# 3066H register map
File version: 1.0
Registers are 32-bit, access per field, reset 0x0 unless marked. A register's access mark holds for its fields unless they carry their own. Offsets are from the block's base; [hi:lo] are bit positions; {n}, {i} and the like mark numbered series; 'fields as' and 'values as' point back to an identical list.

## IOCMG_CORE — IOCMG_CORE peripheral interface
Base 0x147F0000
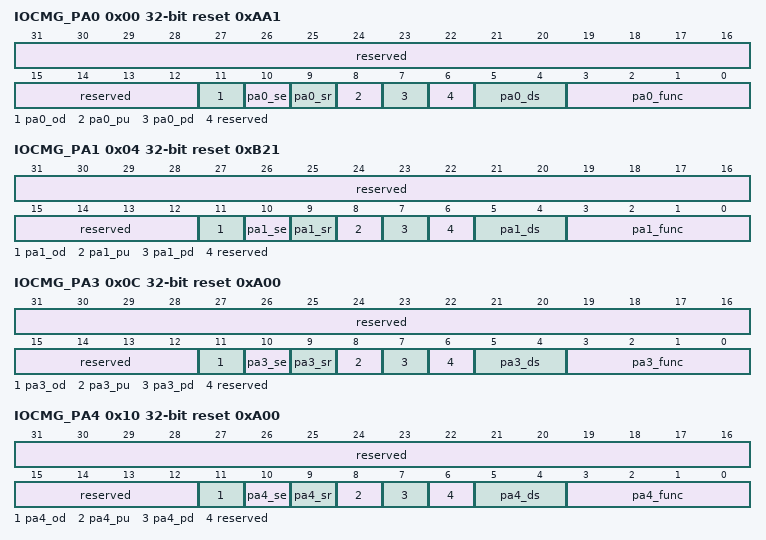
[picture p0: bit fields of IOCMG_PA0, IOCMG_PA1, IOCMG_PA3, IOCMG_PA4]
0x00 IOCMG_PA0 reset 0xAA1 — IOCMG_PA0为PA0管脚控制寄存器。
  [31:12] reserved ro — 保留。
  [11] pa0_od rw — 管脚开漏输出控制。 0：打开； 1：关闭。
  [10] pa0_se rw — 管脚施密特输入控制。 0：关闭； 1：打开。
  [9] pa0_sr rw — 管脚电平转换速率控制。 0：快沿输出； 1：慢沿输出。
  [8] pa0_pu rw — 管脚上拉控制。 0：关闭； 1：打开。
  [7] pa0_pd rw — 管脚下拉控制。 0：关闭； 1：打开。
  [6] reserved ro — 保留。
  [5:4] pa0_ds rw — 管脚驱动能力选择（档位越高，驱动能力越大）。 00：档位1； 01：档位2； 10：档位3； 11：档位4。
  [3:0] pa0_func rw — 管脚复用功能选择。 具体复用功能请参见《3066H系列数据手册》。
0x04 IOCMG_PA1 reset 0xB21 — IOCMG_PA1为PA1管脚控制寄存器。
  [31:12] reserved ro — 保留。
  [11] pa1_od rw — 管脚开漏输出控制。 0：打开； 1：关闭。
  [10] pa1_se rw — 管脚施密特输入控制。 0：关闭； 1：打开。
  [9] pa1_sr rw — 管脚电平转换速率控制。 0：快沿输出； 1：慢沿输出。
  [8] pa1_pu rw — 管脚上拉控制。 0：关闭； 1：打开。
  [7] pa1_pd rw — 管脚下拉控制。 0：关闭； 1：打开。
  [6] reserved ro — 保留。
  [5:4] pa1_ds rw — 管脚驱动能力选择（档位越高，驱动能力越大）。 00：档位1； 01：档位2； 10：档位3； 11：档位4。
  [3:0] pa1_func rw — 管脚复用功能选择。 具体复用功能请参见《3066H系列数据手册》。
0x0C IOCMG_PA3 reset 0xA00 — IOCMG_PA3为PA3管脚控制寄存器。
  [31:12] reserved ro — 保留。
  [11] pa3_od rw — 管脚开漏输出控制。 0：打开； 1：关闭。
  [10] pa3_se rw — 管脚施密特输入控制。 0：关闭； 1：打开。
  [9] pa3_sr rw — 管脚电平转换速率控制。 0：快沿输出； 1：慢沿输出。
  [8] pa3_pu rw — 管脚上拉控制。 0：关闭； 1：打开。
  [7] pa3_pd rw — 管脚下拉控制。 0：关闭； 1：打开。
  [6] reserved ro — 保留。
  [5:4] pa3_ds rw — 管脚驱动能力选择（档位越高，驱动能力越大）。 00：档位1； 01：档位2； 10：档位3； 11：档位4。
  [3:0] pa3_func rw — 管脚复用功能选择。 具体复用功能请参见《3066H系列数据手册》。
0x10 IOCMG_PA4 reset 0xA00 — IOCMG_PA4为PA4管脚控制寄存器。
  [31:12] reserved ro — 保留。
  [11] pa4_od rw — 管脚开漏输出控制。 0：打开； 1：关闭。
  [10] pa4_se rw — 管脚施密特输入控制。 0：关闭； 1：打开。
  [9] pa4_sr rw — 管脚电平转换速率控制。 0：快沿输出； 1：慢沿输出。
  [8] pa4_pu rw — 管脚上拉控制。 0：关闭； 1：打开。
  [7] pa4_pd rw — 管脚下拉控制。 0：关闭； 1：打开。
  [6] reserved ro — 保留。
  [5:4] pa4_ds rw — 管脚驱动能力选择（档位越高，驱动能力越大）。 00：档位1； 01：档位2； 10：档位3； 11：档位4。
  [3:0] pa4_func rw — 管脚复用功能选择。 具体复用功能请参见《3066H系列数据手册》。
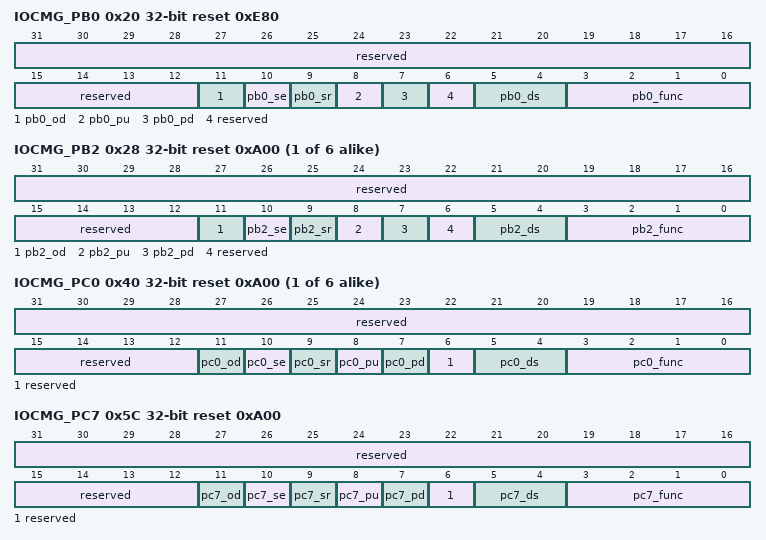
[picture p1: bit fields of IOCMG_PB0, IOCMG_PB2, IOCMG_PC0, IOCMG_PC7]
0x20 IOCMG_PB0 reset 0xE80 — IOCMG_PB0为PB0管脚控制寄存器。
  [31:12] reserved ro — 保留。
  [11] pb0_od rw — 管脚开漏输出控制。 0：打开； 1：关闭。
  [10] pb0_se rw — 管脚施密特输入控制。 0：关闭； 1：打开。
  [9] pb0_sr rw — 管脚电平转换速率控制。 0：快沿输出； 1：慢沿输出。
  [8] pb0_pu rw — 管脚上拉控制。 0：关闭； 1：打开。
  [7] pb0_pd rw — 管脚下拉控制。 0：关闭； 1：打开。
  [6] reserved ro — 保留。
  [5:4] pb0_ds rw — 管脚驱动能力选择（档位越高，驱动能力越大）。 00：档位1； 01：档位2； 10：档位3； 11：档位4。
  [3:0] pb0_func rw — 管脚复用功能选择。 具体复用功能请参见《3066H系列数据手册》。
{0x20+4i} IOCMG_PB{i} reset 0xA00 (i=2..7) — IOCMG_PB{i}为PB{i}管脚控制寄存器。
  [31:12] reserved ro — 保留。
  [11] pb{i}_od rw — 管脚开漏输出控制。 0：打开； 1：关闭。
  [10] pb{i}_se rw — 管脚施密特输入控制。 0：关闭； 1：打开。
  [9] pb{i}_sr rw — 管脚电平转换速率控制。 0：快沿输出； 1：慢沿输出。
  [8] pb{i}_pu rw — 管脚上拉控制。 0：关闭； 1：打开。
  [7] pb{i}_pd rw — 管脚下拉控制。 0：关闭； 1：打开。
  [6] reserved ro — 保留。
  [5:4] pb{i}_ds rw — 管脚驱动能力选择（档位越高，驱动能力越大）。 00：档位1； 01：档位2； 10：档位3； 11：档位4。
  [3:0] pb{i}_func rw — 管脚复用功能选择。 具体复用功能请参见《3066H系列数据手册》。
{0x40+4i} IOCMG_PC{i} reset 0xA00 (i=0..5) — IOCMG_PC{i}为PC{i}管脚控制寄存器。
  [31:12] reserved ro — 保留。
  [11] pc{i}_od rw — 管脚开漏输出控制。 0：打开； 1：关闭。
  [10] pc{i}_se rw — 管脚施密特输入控制。 0：关闭； 1：打开。
  [9] pc{i}_sr rw — 管脚电平转换速率控制。 0：快沿输出； 1：慢沿输出。
  [8] pc{i}_pu rw — 管脚上拉控制。 0：关闭； 1：打开。
  [7] pc{i}_pd rw — 管脚下拉控制。 0：关闭； 1：打开。
  [6] reserved ro — 保留。
  [5:4] pc{i}_ds rw — 管脚驱动能力选择（档位越高，驱动能力越大）。 00：档位1； 01：档位2； 10：档位3； 11：档位4。
  [3:0] pc{i}_func rw — 管脚复用功能选择。 具体复用功能请参见《3066H系列数据手册》。
0x5C IOCMG_PC7 reset 0xA00 — IOCMG_PC7为PC7管脚控制寄存器。
  [31:12] reserved ro — 保留。
  [11] pc7_od rw — 管脚开漏输出控制。 0：打开； 1：关闭。
  [10] pc7_se rw — 管脚施密特输入控制。 0：关闭； 1：打开。
  [9] pc7_sr rw — 管脚电平转换速率控制。 0：快沿输出； 1：慢沿输出。
  [8] pc7_pu rw — 管脚上拉控制。 0：关闭； 1：打开。
  [7] pc7_pd rw — 管脚下拉控制。 0：关闭； 1：打开。
  [6] reserved ro — 保留。
  [5:4] pc7_ds rw — 管脚驱动能力选择（档位越高，驱动能力越大）。 00：档位1； 01：档位2； 10：档位3； 11：档位4。
  [3:0] pc7_func rw — 管脚复用功能选择。 具体复用功能请参见《3066H系列数据手册》。
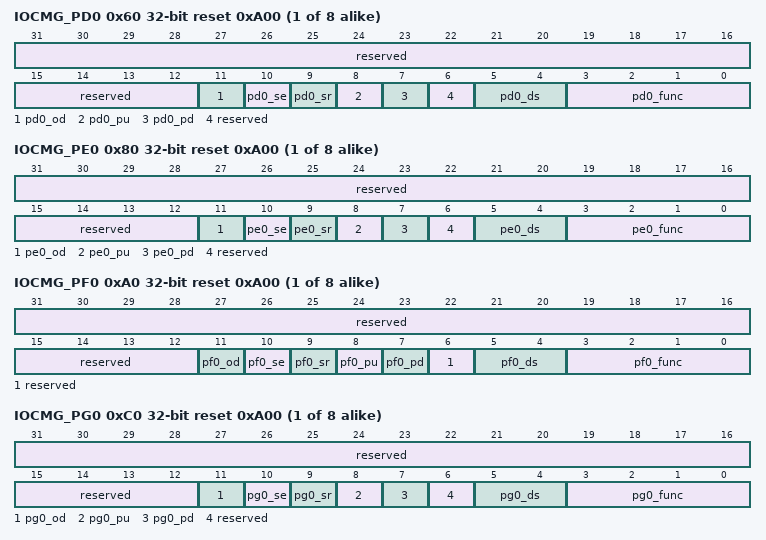
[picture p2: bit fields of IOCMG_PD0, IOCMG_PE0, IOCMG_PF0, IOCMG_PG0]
{0x60+4i} IOCMG_PD{i} reset 0xA00 (i=0..7) — IOCMG_PD{i}为PD{i}管脚控制寄存器。
  [31:12] reserved ro — 保留。
  [11] pd{i}_od rw — 管脚开漏输出控制。 0：打开； 1：关闭。
  [10] pd{i}_se rw — 管脚施密特输入控制。 0：关闭； 1：打开。
  [9] pd{i}_sr rw — 管脚电平转换速率控制。 0：快沿输出； 1：慢沿输出。
  [8] pd{i}_pu rw — 管脚上拉控制。 0：关闭； 1：打开。
  [7] pd{i}_pd rw — 管脚下拉控制。 0：关闭； 1：打开。
  [6] reserved ro — 保留。
  [5:4] pd{i}_ds rw — 管脚驱动能力选择（档位越高，驱动能力越大）。 00：档位1； 01：档位2； 10：档位3； 11：档位4。
  [3:0] pd{i}_func rw — 管脚复用功能选择。 具体复用功能请参见《3066H系列数据手册》。
{0x80+4i} IOCMG_PE{i} reset 0xA00 (i=0..7) — IOCMG_PE{i}为PE{i}管脚控制寄存器。
  [31:12] reserved ro — 保留。
  [11] pe{i}_od rw — 管脚开漏输出控制。 0：打开； 1：关闭。
  [10] pe{i}_se rw — 管脚施密特输入控制。 0：关闭； 1：打开。
  [9] pe{i}_sr rw — 管脚电平转换速率控制。 0：快沿输出； 1：慢沿输出。
  [8] pe{i}_pu rw — 管脚上拉控制。 0：关闭； 1：打开。
  [7] pe{i}_pd rw — 管脚下拉控制。 0：关闭； 1：打开。
  [6] reserved ro — 保留。
  [5:4] pe{i}_ds rw — 管脚驱动能力选择（档位越高，驱动能力越大）。 00：档位1； 01：档位2； 10：档位3； 11：档位4。
  [3:0] pe{i}_func rw — 管脚复用功能选择。 具体复用功能请参见《3066H系列数据手册》。
{0xA0+4i} IOCMG_PF{i} reset 0xA00 (i=0..7) — IOCMG_PF{i}为PF{i}管脚控制寄存器。
  [31:12] reserved ro — 保留。
  [11] pf{i}_od rw — 管脚开漏输出控制。 0：打开； 1：关闭。
  [10] pf{i}_se rw — 管脚施密特输入控制。 0：关闭； 1：打开。
  [9] pf{i}_sr rw — 管脚电平转换速率控制。 0：快沿输出； 1：慢沿输出。
  [8] pf{i}_pu rw — 管脚上拉控制。 0：关闭； 1：打开。
  [7] pf{i}_pd rw — 管脚下拉控制。 0：关闭； 1：打开。
  [6] reserved ro — 保留。
  [5:4] pf{i}_ds rw — 管脚驱动能力选择（档位越高，驱动能力越大）。 00：档位1； 01：档位2； 10：档位3； 11：档位4。
  [3:0] pf{i}_func rw — 管脚复用功能选择。 具体复用功能请参见《3066H系列数据手册》。
{0xC0+4i} IOCMG_PG{i} reset 0xA00 (i=0..7) — IOCMG_PG{i}为PG{i}管脚控制寄存器。
  [31:12] reserved ro — 保留。
  [11] pg{i}_od rw — 管脚开漏输出控制。 0：打开； 1：关闭。
  [10] pg{i}_se rw — 管脚施密特输入控制。 0：关闭； 1：打开。
  [9] pg{i}_sr rw — 管脚电平转换速率控制。 0：快沿输出； 1：慢沿输出。
  [8] pg{i}_pu rw — 管脚上拉控制。 0：关闭； 1：打开。
  [7] pg{i}_pd rw — 管脚下拉控制。 0：关闭； 1：打开。
  [6] reserved ro — 保留。
  [5:4] pg{i}_ds rw — 管脚驱动能力选择（档位越高，驱动能力越大）。 00：档位1； 01：档位2； 10：档位3； 11：档位4。
  [3:0] pg{i}_func rw — 管脚复用功能选择。 具体复用功能请参见《3066H系列数据手册》。
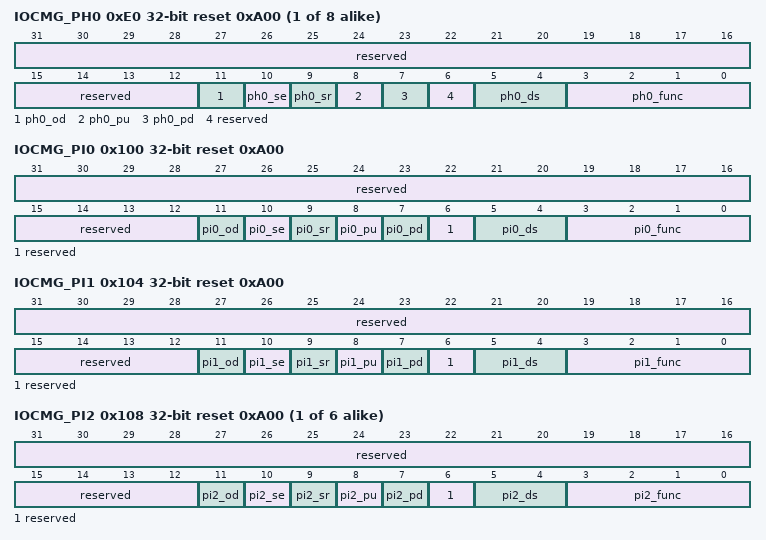
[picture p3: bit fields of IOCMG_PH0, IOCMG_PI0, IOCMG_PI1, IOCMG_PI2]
{0xE0+4i} IOCMG_PH{i} reset 0xA00 (i=0..7) — IOCMG_PH{i}为PH{i}管脚控制寄存器。
  [31:12] reserved ro — 保留。
  [11] ph{i}_od rw — 管脚开漏输出控制。 0：打开； 1：关闭。
  [10] ph{i}_se rw — 管脚施密特输入控制。 0：关闭； 1：打开。
  [9] ph{i}_sr rw — 管脚电平转换速率控制。 0：快沿输出； 1：慢沿输出。
  [8] ph{i}_pu rw — 管脚上拉控制。 0：关闭； 1：打开。
  [7] ph{i}_pd rw — 管脚下拉控制。 0：关闭； 1：打开。
  [6] reserved ro — 保留。
  [5:4] ph{i}_ds rw — 管脚驱动能力选择（档位越高，驱动能力越大）。 00：档位1； 01：档位2； 10：档位3； 11：档位4。
  [3:0] ph{i}_func rw — 管脚复用功能选择。 具体复用功能请参见《3066H系列数据手册》。
0x100 IOCMG_PI0 reset 0xA00 — IOCMG_PI0为PI0管脚控制寄存器。
  [31:12] reserved ro — 保留。
  [11] pi0_od rw — 管脚开漏输出控制。 0：打开； 1：关闭。
  [10] pi0_se rw — 管脚施密特输入控制。 0：关闭； 1：打开。
  [9] pi0_sr rw — 管脚电平转换速率控制。 0：快沿输出； 1：慢沿输出。
  [8] pi0_pu rw — 管脚上拉控制。 0：关闭； 1：打开。
  [7] pi0_pd rw — 管脚下拉控制。 0：关闭； 1：打开。
  [6] reserved ro — 保留。
  [5:4] pi0_ds rw — 管脚驱动能力选择（档位越高，驱动能力越大）。 00：档位1； 01：档位2； 10：档位3； 11：档位4。
  [3:0] pi0_func rw — 管脚复用功能选择。 具体复用功能请参见《3066H系列数据手册》。
0x104 IOCMG_PI1 reset 0xA00 — IOCMG_PI1为PI1管脚控制寄存器。
  [31:12] reserved ro — 保留。
  [11] pi1_od rw — 管脚开漏输出控制。 0：打开； 1：关闭。
  [10] pi1_se rw — 管脚施密特输入控制。 0：关闭； 1：打开。
  [9] pi1_sr rw — 管脚电平转换速率控制。 0：快沿输出； 1：慢沿输出。
  [8] pi1_pu rw — 管脚上拉控制。 0：关闭； 1：打开。
  [7] pi1_pd rw — 管脚下拉控制。 0：关闭； 1：打开。
  [6] reserved ro — 保留。
  [5:4] pi1_ds rw — 管脚驱动能力选择（档位越高，驱动能力越大）。 00：档位1； 01：档位2； 10：档位3； 11：档位4。
  [3:0] pi1_func rw — 管脚复用功能选择。具体复用功能请参见《3066H系列数据手册》。
{0x100+4i} IOCMG_PI{i} reset 0xA00 (i=2..7) — IOCMG_PI{i}为PI{i}管脚控制寄存器。
  [31:12] reserved ro — 保留。
  [11] pi{i}_od rw — 管脚开漏输出控制。 0：打开； 1：关闭。
  [10] pi{i}_se rw — 管脚施密特输入控制。 0：关闭； 1：打开。
  [9] pi{i}_sr rw — 管脚电平转换速率控制。 0：快沿输出； 1：慢沿输出。
  [8] pi{i}_pu rw — 管脚上拉控制。 0：关闭； 1：打开。
  [7] pi{i}_pd rw — 管脚下拉控制。 0：关闭； 1：打开。
  [6] reserved ro — 保留。
  [5:4] pi{i}_ds rw — 管脚驱动能力选择（档位越高，驱动能力越大）。 00：档位1； 01：档位2； 10：档位3； 11：档位4。
  [3:0] pi{i}_func rw — 管脚复用功能选择。 具体复用功能请参见《3066H系列数据手册》。
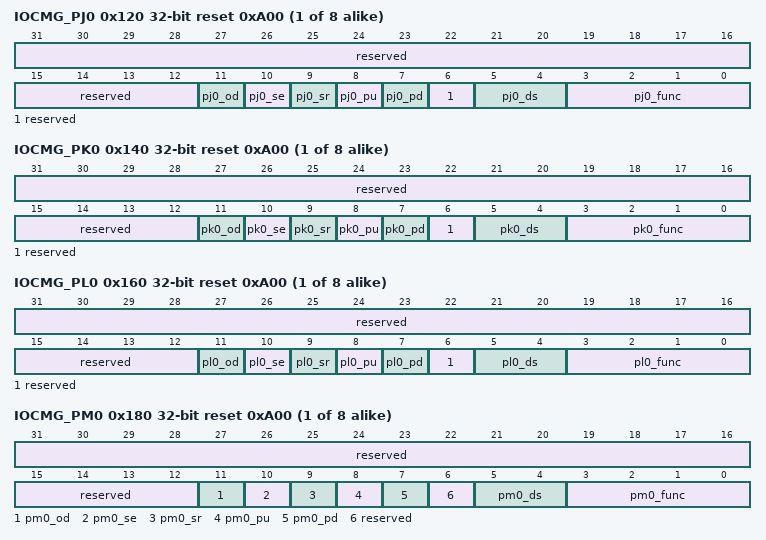
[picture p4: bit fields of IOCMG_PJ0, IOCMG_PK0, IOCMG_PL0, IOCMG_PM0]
{0x120+4i} IOCMG_PJ{i} reset 0xA00 (i=0..7) — IOCMG_PJ{i}为PJ{i}管脚控制寄存器。
  [31:12] reserved ro — 保留。
  [11] pj{i}_od rw — 管脚开漏输出控制。 0：打开； 1：关闭。
  [10] pj{i}_se rw — 管脚施密特输入控制。 0：关闭； 1：打开。
  [9] pj{i}_sr rw — 管脚电平转换速率控制。 0：快沿输出； 1：慢沿输出。
  [8] pj{i}_pu rw — 管脚上拉控制。 0：关闭； 1：打开。
  [7] pj{i}_pd rw — 管脚下拉控制。 0：关闭； 1：打开。
  [6] reserved ro — 保留。
  [5:4] pj{i}_ds rw — 管脚驱动能力选择（档位越高，驱动能力越大）。 00：档位1； 01：档位2； 10：档位3； 11：档位4。
  [3:0] pj{i}_func rw — 管脚复用功能选择。 具体复用功能请参见《3066H系列数据手册》。
{0x140+4i} IOCMG_PK{i} reset 0xA00 (i=0..7) — IOCMG_PK{i}为PK{i}管脚控制寄存器。
  [31:12] reserved ro — 保留。
  [11] pk{i}_od rw — 管脚开漏输出控制。 0：打开； 1：关闭。
  [10] pk{i}_se rw — 管脚施密特输入控制。 0：关闭； 1：打开。
  [9] pk{i}_sr rw — 管脚电平转换速率控制。 0：快沿输出； 1：慢沿输出。
  [8] pk{i}_pu rw — 管脚上拉控制。 0：关闭； 1：打开。
  [7] pk{i}_pd rw — 管脚下拉控制。 0：关闭； 1：打开。
  [6] reserved ro — 保留。
  [5:4] pk{i}_ds rw — 管脚驱动能力选择（档位越高，驱动能力越大）。 00：档位1； 01：档位2； 10：档位3； 11：档位4。
  [3:0] pk{i}_func rw — 管脚复用功能选择。 具体复用功能请参见《3066H系列数据手册》。
{0x160+4i} IOCMG_PL{i} reset 0xA00 (i=0..7) — IOCMG_PL{i}为PL{i}管脚控制寄存器。
  [31:12] reserved ro — 保留。
  [11] pl{i}_od rw — 管脚开漏输出控制。 0：打开； 1：关闭。
  [10] pl{i}_se rw — 管脚施密特输入控制。 0：关闭； 1：打开。
  [9] pl{i}_sr rw — 管脚电平转换速率控制。 0：快沿输出； 1：慢沿输出。
  [8] pl{i}_pu rw — 管脚上拉控制。 0：关闭； 1：打开。
  [7] pl{i}_pd rw — 管脚下拉控制。 0：关闭； 1：打开。
  [6] reserved ro — 保留。
  [5:4] pl{i}_ds rw — 管脚驱动能力选择（档位越高，驱动能力越大）。 00：档位1； 01：档位2； 10：档位3； 11：档位4。
  [3:0] pl{i}_func rw — 管脚复用功能选择。 具体复用功能请参见《3066H系列数据手册》。
{0x180+4i} IOCMG_PM{i} reset 0xA00 (i=0..7) — IOCMG_PM{i}为PM{i}管脚控制寄存器。
  [31:12] reserved ro — 保留。
  [11] pm{i}_od rw — 管脚开漏输出控制。 0：打开； 1：关闭。
  [10] pm{i}_se rw — 管脚施密特输入控制。 0：关闭； 1：打开。
  [9] pm{i}_sr rw — 管脚电平转换速率控制。 0：快沿输出； 1：慢沿输出。
  [8] pm{i}_pu rw — 管脚上拉控制。 0：关闭； 1：打开。
  [7] pm{i}_pd rw — 管脚下拉控制。 0：关闭； 1：打开。
  [6] reserved ro — 保留。
  [5:4] pm{i}_ds rw — 管脚驱动能力选择（档位越高，驱动能力越大）。 00：档位1； 01：档位2； 10：档位3； 11：档位4。
  [3:0] pm{i}_func rw — 管脚复用功能选择。 具体复用功能请参见《3066H系列数据手册》。
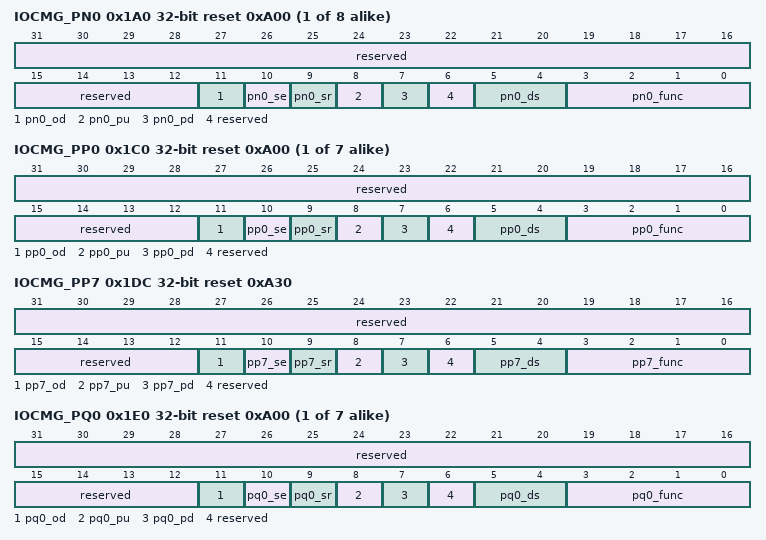
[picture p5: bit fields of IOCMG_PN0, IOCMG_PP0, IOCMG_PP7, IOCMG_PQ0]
{0x1A0+4i} IOCMG_PN{i} reset 0xA00 (i=0..7) — IOCMG_PN{i}为PN{i}管脚控制寄存器。
  [31:12] reserved ro — 保留。
  [11] pn{i}_od rw — 管脚开漏输出控制。 0：打开； 1：关闭。
  [10] pn{i}_se rw — 管脚施密特输入控制。 0：关闭； 1：打开。
  [9] pn{i}_sr rw — 管脚电平转换速率控制。 0：快沿输出； 1：慢沿输出。
  [8] pn{i}_pu rw — 管脚上拉控制。 0：关闭； 1：打开。
  [7] pn{i}_pd rw — 管脚下拉控制。 0：关闭； 1：打开。
  [6] reserved ro — 保留。
  [5:4] pn{i}_ds rw — 管脚驱动能力选择（档位越高，驱动能力越大）。 00：档位1； 01：档位2； 10：档位3； 11：档位4。
  [3:0] pn{i}_func rw — 管脚复用功能选择。 具体复用功能请参见《3066H系列数据手册》。
{0x1C0+4i} IOCMG_PP{i} reset 0xA00 (i=0..6) — IOCMG_PP{i}为PP{i}管脚控制寄存器。
  [31:12] reserved ro — 保留。
  [11] pp{i}_od rw — 管脚开漏输出控制。 0：打开； 1：关闭。
  [10] pp{i}_se rw — 管脚施密特输入控制。 0：关闭； 1：打开。
  [9] pp{i}_sr rw — 管脚电平转换速率控制。 0：快沿输出； 1：慢沿输出。
  [8] pp{i}_pu rw — 管脚上拉控制。 0：关闭； 1：打开。
  [7] pp{i}_pd rw — 管脚下拉控制。 0：关闭； 1：打开。
  [6] reserved ro — 保留。
  [5:4] pp{i}_ds rw — 管脚驱动能力选择（档位越高，驱动能力越大）。 00：档位1； 01：档位2； 10：档位3； 11：档位4。
  [3:0] pp{i}_func rw — 管脚复用功能选择。 具体复用功能请参见《3066H系列数据手册》。
0x1DC IOCMG_PP7 reset 0xA30 — IOCMG_PP7为PP7管脚控制寄存器。
  [31:12] reserved ro — 保留。
  [11] pp7_od rw — 管脚开漏输出控制。 0：打开； 1：关闭。
  [10] pp7_se rw — 管脚施密特输入控制。 0：关闭； 1：打开。
  [9] pp7_sr rw — 管脚电平转换速率控制。 0：快沿输出； 1：慢沿输出。
  [8] pp7_pu rw — 管脚上拉控制。 0：关闭； 1：打开。
  [7] pp7_pd rw — 管脚下拉控制。 0：关闭； 1：打开。
  [6] reserved ro — 保留。
  [5:4] pp7_ds rw — 管脚驱动能力选择（档位越高，驱动能力越大）。 00：档位1； 01：档位2； 10：档位3； 11：档位4。
  [3:0] pp7_func rw — 管脚复用功能选择。 具体复用功能请参见《3066H系列数据手册》。
{0x1E0+4i} IOCMG_PQ{i} reset 0xA00 (i=0..6) — IOCMG_PQ{i}为PQ{i}管脚控制寄存器。
  [31:12] reserved ro — 保留。
  [11] pq{i}_od rw — 管脚开漏输出控制。 0：打开； 1：关闭。
  [10] pq{i}_se rw — 管脚施密特输入控制。 0：关闭； 1：打开。
  [9] pq{i}_sr rw — 管脚电平转换速率控制。 0：快沿输出； 1：慢沿输出。
  [8] pq{i}_pu rw — 管脚上拉控制。 0：关闭； 1：打开。
  [7] pq{i}_pd rw — 管脚下拉控制。 0：关闭； 1：打开。
  [6] reserved ro — 保留。
  [5:4] pq{i}_ds rw — 管脚驱动能力选择（档位越高，驱动能力越大）。 00：档位1； 01：档位2； 10：档位3； 11：档位4。
  [3:0] pq{i}_func rw — 管脚复用功能选择。 具体复用功能请参见《3066H系列数据手册》。
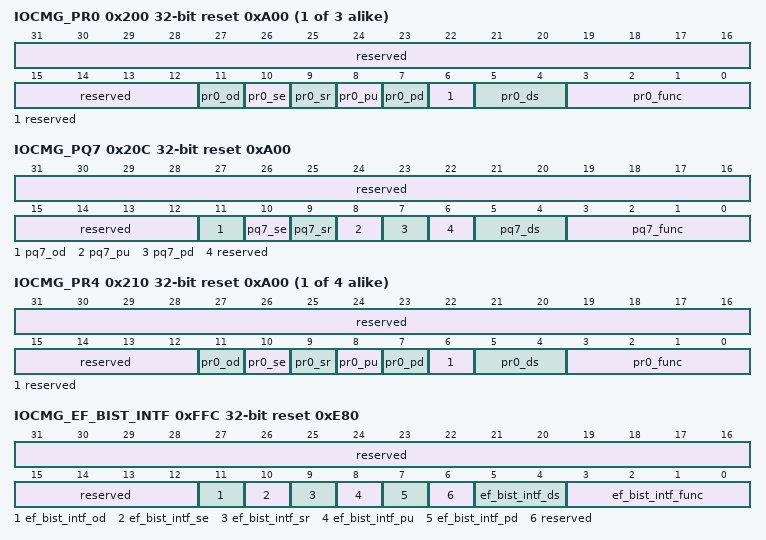
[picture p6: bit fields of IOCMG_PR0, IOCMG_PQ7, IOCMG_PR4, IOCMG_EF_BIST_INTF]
{0x200+4i} IOCMG_PR{i} reset 0xA00 (i=0..2) — IOCMG_PR{i}为PR{i}管脚控制寄存器。
  [31:12] reserved ro — 保留。
  [11] pr{i}_od rw — 管脚开漏输出控制。 0：打开； 1：关闭。
  [10] pr{i}_se rw — 管脚施密特输入控制。 0：关闭； 1：打开。
  [9] pr{i}_sr rw — 管脚电平转换速率控制。 0：快沿输出； 1：慢沿输出。
  [8] pr{i}_pu rw — 管脚上拉控制。 0：关闭； 1：打开。
  [7] pr{i}_pd rw — 管脚下拉控制。 0：关闭； 1：打开。
  [6] reserved ro — 保留。
  [5:4] pr{i}_ds rw — 管脚驱动能力选择（档位越高，驱动能力越大）。 00：档位1； 01：档位2； 10：档位3； 11：档位4。
  [3:0] pr{i}_func rw — 管脚复用功能选择。 具体复用功能请参见《3066H系列数据手册》。
0x20C IOCMG_PQ7 reset 0xA00 — IOCMG_PQ7为PQ7管脚控制寄存器。
  [31:12] reserved ro — 保留。
  [11] pq7_od rw — 管脚开漏输出控制。 0：打开； 1：关闭。
  [10] pq7_se rw — 管脚施密特输入控制。 0：关闭； 1：打开。
  [9] pq7_sr rw — 管脚电平转换速率控制。 0：快沿输出； 1：慢沿输出。
  [8] pq7_pu rw — 管脚上拉控制。 0：关闭； 1：打开。
  [7] pq7_pd rw — 管脚下拉控制。 0：关闭； 1：打开。
  [6] reserved ro — 保留。
  [5:4] pq7_ds rw — 管脚驱动能力选择（档位越高，驱动能力越大）。 00：档位1； 01：档位2； 10：档位3； 11：档位4。
  [3:0] pq7_func rw — 管脚复用功能选择。 具体复用功能请参见《3066H系列数据手册》。
{0x200+4i} IOCMG_PR{i} reset 0xA00 (i=4..7) — IOCMG_PR{i}为PR{i}管脚控制寄存器。
  fields as IOCMG_PR0
0xFFC IOCMG_EF_BIST_INTF reset 0xE80 — IOCMG_EF_BIST_INTF为IOCMG_EF_BIST_INTF管脚控制寄存器。
  [31:12] reserved ro — 保留。
  [11] ef_bist_intf_od rw — 管脚开漏输出控制。 0：打开； 1：关闭。
  [10] ef_bist_intf_se rw — 管脚施密特输入控制。 0：关闭； 1：打开。
  [9] ef_bist_intf_sr rw — 管脚电平转换速率控制。 0：快沿输出； 1：慢沿输出。
  [8] ef_bist_intf_pu rw — 管脚上拉控制。 0：关闭； 1：打开。
  [7] ef_bist_intf_pd rw — 管脚下拉控制。 0：关闭； 1：打开。
  [6] reserved ro — 保留。
  [5:4] ef_bist_intf_ds rw — 管脚驱动能力选择（档位越高，驱动能力越大）。 00：档位1； 01：档位2； 10：档位3； 11：档位4。
  [3:0] ef_bist_intf_func rw — 管脚复用功能选择。 具体复用功能请参见《3066H系列数据手册》。
